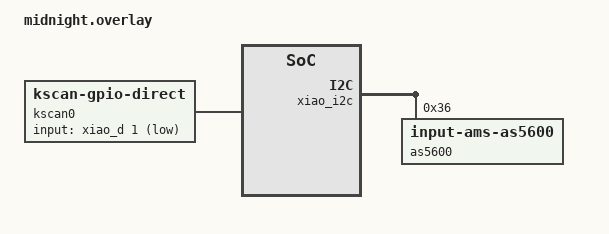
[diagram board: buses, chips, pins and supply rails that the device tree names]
#include <dt-bindings/zmk/matrix_transform.h>
#include <input/processors.h>

/ {
    chosen {
        zmk,kscan = &kscan0;
        zmk,matrix-transform = &default_transform;
    };

    default_transform: keymap_transform_0 {
        compatible = "zmk,matrix-transform";
        columns = <1>;
        rows = <1>;
        map = <RC(0,0)>;
    };

    /* One push-button (wheel click) between D1 and GND */
    kscan0: kscan_0 {
        compatible = "zmk,kscan-gpio-direct";
        wakeup-source;
        input-gpios = <&xiao_d 1 (GPIO_ACTIVE_LOW | GPIO_PULL_UP)>;
    };

    as5600_listener: as5600_listener {
        compatible = "zmk,input-listener";
        device = <&as5600>;
        /* <multiplier divisor>; negative flips direction.
           Tune this for feel. */
        input-processors = <&zip_scroll_scaler (-2) 1>;
    };
};

/* XIAO nRF52840: SDA = D4, SCL = D5 */
&xiao_i2c {
    compatible = "nordic,nrf-twi";
    pinctrl-0 = <&i2c0_default>;
    pinctrl-1 = <&i2c0_sleep>;
    pinctrl-names = "default", "sleep";
    status = "okay";

    as5600: as5600@36 {
        compatible = "zmk,input-ams-as5600";
        reg = <0x36>;
        status = "okay";
    };
};
